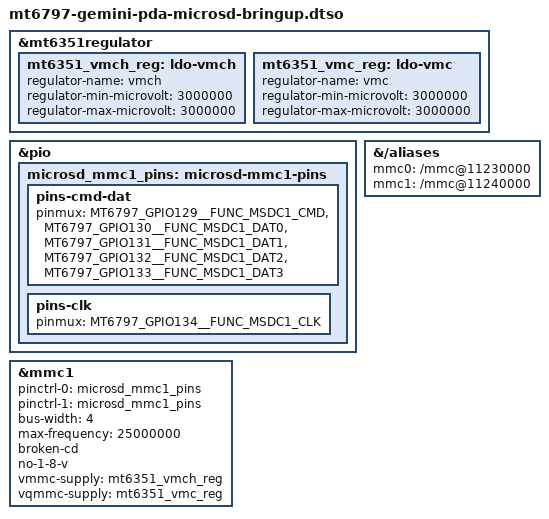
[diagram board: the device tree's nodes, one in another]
// SPDX-License-Identifier: GPL-2.0-only
/*
 * Gemini MSDC1: polled card presence, 4-bit legacy SD at 25 MHz / 3.0 V.
 * Hardware testing on 2026-09-03 found GPIO67 unchanged with and without a
 * card. Vendor insertion uses a separate device, so GPIO67 is not a valid
 * generic cd-gpios input. Polling enumerated the SDABC 29.1 GiB card.
 *
 * Keep the established GPIO129..134 MSDC1 mux and MT6351 VMCH/VMC 3.0 V
 * supplies. No high-speed/UHS modes or 1.8 V switching are advertised.
 * Explicit aliases keep the eMMC and removable controller numbering stable;
 * callers must still verify controller lineage before accessing a block node.
 */

/dts-v1/;
/plugin/;

#include <dt-bindings/pinctrl/mt6797-pinfunc.h>

&mt6351regulator {
	/* Vendor MMC1 card rail: VMCH, constrained to its 3.0 V mode. */
	mt6351_vmch_reg: ldo-vmch {
		regulator-name = "vmch";
		regulator-min-microvolt = <3000000>;
		regulator-max-microvolt = <3000000>;
	};

	/* Vendor MMC1 signalling rail: VMC, kept out of the 1.8 V UHS mode. */
	mt6351_vmc_reg: ldo-vmc {
		regulator-name = "vmc";
		regulator-min-microvolt = <3000000>;
		regulator-max-microvolt = <3000000>;
	};
};

&pio {
	microsd_mmc1_pins: microsd-mmc1-pins {
		pins-cmd-dat {
			pinmux = <MT6797_GPIO129__FUNC_MSDC1_CMD>,
				 <MT6797_GPIO130__FUNC_MSDC1_DAT0>,
				 <MT6797_GPIO131__FUNC_MSDC1_DAT1>,
				 <MT6797_GPIO132__FUNC_MSDC1_DAT2>,
				 <MT6797_GPIO133__FUNC_MSDC1_DAT3>;
		};

		pins-clk {
			pinmux = <MT6797_GPIO134__FUNC_MSDC1_CLK>;
		};
	};

};

&mmc1 {
	pinctrl-names = "default", "state_uhs";
	pinctrl-0 = <&microsd_mmc1_pins>;
	/* No electrical UHS transition is permitted; retain the 3.0 V state. */
	pinctrl-1 = <&microsd_mmc1_pins>;

	bus-width = <4>;
	/* Legacy SD default speed: below the unmodelled high-speed pad contract. */
	max-frequency = <25000000>;
	broken-cd;
	no-1-8-v;
	vmmc-supply = <&mt6351_vmch_reg>;
	vqmmc-supply = <&mt6351_vmc_reg>;
	status = "okay";
};

&{/aliases} {
	mmc0 = "/mmc@11230000";
	mmc1 = "/mmc@11240000";
};
